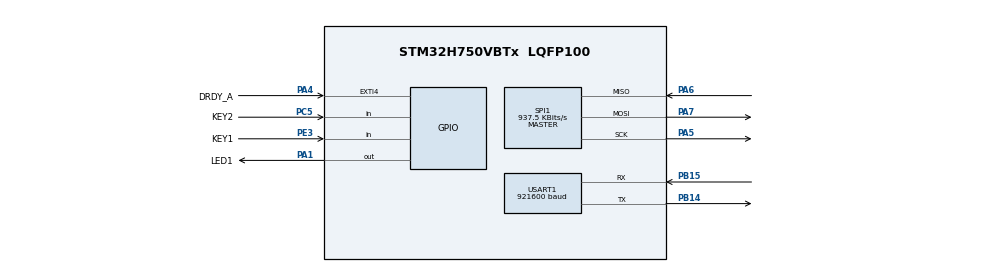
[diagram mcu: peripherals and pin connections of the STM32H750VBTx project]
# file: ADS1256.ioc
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Dma.Request0=USART1_TX
Dma.USART1_TX.0.Direction=DMA_MEMORY_TO_PERIPH
Dma.USART1_TX.0.EventEnable=DISABLE
Dma.USART1_TX.0.FIFOMode=DMA_FIFOMODE_DISABLE
Dma.USART1_TX.0.Instance=DMA1_Stream0
Dma.USART1_TX.0.MemDataAlignment=DMA_MDATAALIGN_BYTE
Dma.USART1_TX.0.MemInc=DMA_MINC_ENABLE
Dma.USART1_TX.0.Mode=DMA_NORMAL
Dma.USART1_TX.0.PeriphDataAlignment=DMA_PDATAALIGN_BYTE
Dma.USART1_TX.0.PeriphInc=DMA_PINC_DISABLE
Dma.USART1_TX.0.Polarity=HAL_DMAMUX_REQ_GEN_RISING
Dma.USART1_TX.0.Priority=DMA_PRIORITY_LOW
Dma.USART1_TX.0.RequestNumber=1
Dma.USART1_TX.0.SignalID=NONE
Dma.USART1_TX.0.SyncEnable=DISABLE
Dma.USART1_TX.0.SyncPolarity=HAL_DMAMUX_SYNC_NO_EVENT
Dma.USART1_TX.0.SyncRequestNumber=1
Dma.USART1_TX.0.SyncSignalID=NONE
FREERTOS.Tasks01=Task01,24,128,StartDefaultTask,Default,NULL,Dynamic,NULL,NULL;Task02,24,128,StartTask02,Default,NULL,Dynamic,NULL,NULL;Task03,24,128,StartTask03,Default,NULL,Dynamic,NULL,NULL
Mcu.Family=STM32H7
Mcu.Name=STM32H750VBTx
Mcu.Package=LQFP100
NVIC.DMA1_Stream0_IRQn=true\:5\:0\:false\:false\:true\:true\:false\:true
NVIC.EXTI4_IRQn=true\:5\:0\:false\:false\:true\:true\:true\:true
NVIC.PriorityGroup=NVIC_PRIORITYGROUP_4
NVIC.TIM17_IRQn=true\:0\:0\:false\:false\:true\:false\:false\:true
NVIC.TimeBase=TIM17_IRQn
NVIC.TimeBaseIP=TIM17
NVIC.USART1_IRQn=true\:5\:0\:false\:false\:true\:true\:true\:true
PA1.GPIO_Label=LED1
PA1.Signal=GPIO_Output
PA13\ (JTMS/SWDIO).Mode=Serial_Wire
PA13\ (JTMS/SWDIO).Signal=DEBUG_JTMS-SWDIO
PA14\ (JTCK/SWCLK).Mode=Serial_Wire
PA14\ (JTCK/SWCLK).Signal=DEBUG_JTCK-SWCLK
PA4.GPIO_Label=DRDY_A
PA4.GPIO_ModeDefaultEXTI=GPIO_MODE_IT_FALLING
PA4.Signal=GPXTI4
PA5.Mode=Full_Duplex_Master
PA5.Signal=SPI1_SCK
PA6.Mode=Full_Duplex_Master
PA6.Signal=SPI1_MISO
PA7.Mode=Full_Duplex_Master
PA7.Signal=SPI1_MOSI
PB14.Mode=Asynchronous
PB14.Signal=USART1_TX
PB15.Mode=Asynchronous
PB15.Signal=USART1_RX
PC5.GPIO_Label=KEY2
PC5.GPIO_PuPd=GPIO_PULLUP
PC5.Signal=GPIO_Input
PE3.GPIO_Label=KEY1
PE3.GPIO_PuPd=GPIO_PULLUP
PE3.Signal=GPIO_Input
PH0-OSC_IN\ (PH0).Mode=HSE-External-Oscillator
PH0-OSC_IN\ (PH0).Signal=RCC_OSC_IN
PH1-OSC_OUT\ (PH1).Mode=HSE-External-Oscillator
PH1-OSC_OUT\ (PH1).Signal=RCC_OSC_OUT
ProjectManager.HeapSize=0x200
ProjectManager.StackSize=0x400
ProjectManager.TargetToolchain=MDK-ARM V5.27
RCC.ADCFreq_Value=60000000
RCC.APB1Freq_Value=120000000
RCC.APB2Freq_Value=120000000
RCC.APB3Freq_Value=120000000
RCC.APB4Freq_Value=120000000
RCC.CortexFreq_Value=480000000
RCC.D1PPRE=RCC_APB3_DIV2
RCC.D2PPRE1=RCC_APB1_DIV2
RCC.D2PPRE2=RCC_APB2_DIV2
RCC.D3PPRE=RCC_APB4_DIV2
RCC.DIVM1=5
RCC.DIVM2=5
RCC.DIVM3=5
RCC.DIVN1=192
RCC.DIVN2=48
RCC.DIVN3=48
RCC.DIVP2=4
RCC.HCLKFreq_Value=240000000
RCC.HPRE=RCC_HCLK_DIV2
RCC.PLL2FRACN=0
RCC.PLLSourceVirtual=RCC_PLLSOURCE_HSE
RCC.SPI123CLockSelection=RCC_SPI123CLKSOURCE_PLL2
RCC.SYSCLKFreq_VALUE=480000000
RCC.SYSCLKSource=RCC_SYSCLKSOURCE_PLLCLK
RCC.USBFreq_Value=480000000
SPI1.BaudRatePrescaler=SPI_BAUDRATEPRESCALER_64
SPI1.CLKPhase=SPI_PHASE_2EDGE
SPI1.CalculateBaudRate=937.5 KBits/s
SPI1.DataSize=SPI_DATASIZE_8BIT
SPI1.Direction=SPI_DIRECTION_2LINES
SPI1.Mode=SPI_MODE_MASTER
SPI1.VirtualType=VM_MASTER
USART1.BaudRate=921600
USART1.OverSampling=UART_OVERSAMPLING_8
USART1.VirtualMode-Asynchronous=VM_ASYNC
VP_FREERTOS_VS_CMSIS_V2.Mode=CMSIS_V2
VP_SYS_VS_tim17.Mode=TIM17
board=custom

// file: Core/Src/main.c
/* USER CODE BEGIN Header */
/**
  ******************************************************************************
  * @file           : main.c
  * @brief          : Main program body
  ******************************************************************************
  * @attention
  *
  * <h2><center>&copy; Copyright (c) 2021 STMicroelectronics.
  * All rights reserved.</center></h2>
  *
  * This software component is licensed by ST under Ultimate Liberty license
  * SLA0044, the "License"; You may not use this file except in compliance with
  * the License. You may obtain a copy of the License at:
  *                             www.st.com/SLA0044
  *
  ******************************************************************************
  */
/* USER CODE END Header */
#include "main.h"
#include "cmsis_os.h"
#include "dma.h"
#include "spi.h"
#include "usart.h"
#include "gpio.h"

void SystemClock_Config(void);
void MX_FREERTOS_Init(void);

int main(void)
{

  /* MCU Configuration--------------------------------------------------------*/

  /* Reset of all peripherals, Initializes the Flash interface and the Systick. */
  HAL_Init();

  /* Configure the system clock */
  SystemClock_Config();

  /* Initialize all configured peripherals */
  MX_GPIO_Init();
  MX_DMA_Init();
  MX_SPI1_Init();
  MX_USART1_UART_Init();

  /* Init scheduler */
  osKernelInitialize();  /* Call init function for freertos objects (in freertos.c) */
  MX_FREERTOS_Init();
  /* Start scheduler */
  osKernelStart();

  /* We should never get here as control is now taken by the scheduler */
  /* Infinite loop */
  while (1)
  {

  }
}

void SystemClock_Config(void)
{
  RCC_OscInitTypeDef RCC_OscInitStruct = {0};
  RCC_ClkInitTypeDef RCC_ClkInitStruct = {0};

  /** Supply configuration update enable
  */
  HAL_PWREx_ConfigSupply(PWR_LDO_SUPPLY);
  /** Configure the main internal regulator output voltage
  */
  __HAL_PWR_VOLTAGESCALING_CONFIG(PWR_REGULATOR_VOLTAGE_SCALE0);

  while(!__HAL_PWR_GET_FLAG(PWR_FLAG_VOSRDY)) {}
  /** Macro to configure the PLL clock source
  */
  __HAL_RCC_PLL_PLLSOURCE_CONFIG(RCC_PLLSOURCE_HSE);
  /** Initializes the RCC Oscillators according to the specified parameters
  * in the RCC_OscInitTypeDef structure.
  */
  RCC_OscInitStruct.OscillatorType = RCC_OSCILLATORTYPE_HSE;
  RCC_OscInitStruct.HSEState = RCC_HSE_ON;
  RCC_OscInitStruct.PLL.PLLState = RCC_PLL_ON;
  RCC_OscInitStruct.PLL.PLLSource = RCC_PLLSOURCE_HSE;
  RCC_OscInitStruct.PLL.PLLM = 5;
  RCC_OscInitStruct.PLL.PLLN = 192;
  RCC_OscInitStruct.PLL.PLLP = 2;
  RCC_OscInitStruct.PLL.PLLQ = 2;
  RCC_OscInitStruct.PLL.PLLR = 2;
  RCC_OscInitStruct.PLL.PLLRGE = RCC_PLL1VCIRANGE_2;
  RCC_OscInitStruct.PLL.PLLVCOSEL = RCC_PLL1VCOWIDE;
  RCC_OscInitStruct.PLL.PLLFRACN = 0;
  if (HAL_RCC_OscConfig(&RCC_OscInitStruct) != HAL_OK)
  {
    Error_Handler();
  }
  /** Initializes the CPU, AHB and APB buses clocks
  */
  RCC_ClkInitStruct.ClockType = RCC_CLOCKTYPE_HCLK|RCC_CLOCKTYPE_SYSCLK
                              |RCC_CLOCKTYPE_PCLK1|RCC_CLOCKTYPE_PCLK2
                              |RCC_CLOCKTYPE_D3PCLK1|RCC_CLOCKTYPE_D1PCLK1;
  RCC_ClkInitStruct.SYSCLKSource = RCC_SYSCLKSOURCE_PLLCLK;
  RCC_ClkInitStruct.SYSCLKDivider = RCC_SYSCLK_DIV1;
  RCC_ClkInitStruct.AHBCLKDivider = RCC_HCLK_DIV2;
  RCC_ClkInitStruct.APB3CLKDivider = RCC_APB3_DIV2;
  RCC_ClkInitStruct.APB1CLKDivider = RCC_APB1_DIV2;
  RCC_ClkInitStruct.APB2CLKDivider = RCC_APB2_DIV2;
  RCC_ClkInitStruct.APB4CLKDivider = RCC_APB4_DIV2;

  if (HAL_RCC_ClockConfig(&RCC_ClkInitStruct, FLASH_LATENCY_4) != HAL_OK)
  {
    Error_Handler();
  }
}

 /**
  * @brief  Period elapsed callback in non blocking mode
  * @note   This function is called  when TIM17 interrupt took place, inside
  * HAL_TIM_IRQHandler(). It makes a direct call to HAL_IncTick() to increment
  * a global variable "uwTick" used as application time base.
  * @param  htim : TIM handle
  * @retval None
  */
void HAL_TIM_PeriodElapsedCallback(TIM_HandleTypeDef *htim)
{
  if (htim->Instance == TIM17) {
    HAL_IncTick();
  }
}

void Error_Handler(void)
{
  __disable_irq();
  while (1)
  {
  }
}

/************************ (C) COPYRIGHT STMicroelectronics *****END OF FILE****/

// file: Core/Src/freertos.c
/* USER CODE BEGIN Header */
/**
  ******************************************************************************
  * File Name          : freertos.c
  * Description        : Code for freertos applications
  ******************************************************************************
  * @attention
  *
  * <h2><center>&copy; Copyright (c) 2021 STMicroelectronics.
  * All rights reserved.</center></h2>
  *
  * This software component is licensed by ST under Ultimate Liberty license
  * SLA0044, the "License"; You may not use this file except in compliance with
  * the License. You may obtain a copy of the License at:
  *                             www.st.com/SLA0044
  *
  ******************************************************************************
  */
/* USER CODE END Header */

#include "FreeRTOS.h"
#include "task.h"
#include "main.h"
#include "cmsis_os.h"

/* USER CODE BEGIN Includes */
#include "Task01.h"
#include "Task02.h"
#include "Task03.h"
/* USER CODE END Includes */

/* Definitions for Task01 */
osThreadId_t Task01Handle;
const osThreadAttr_t Task01_attributes = {
  .name = "Task01",
  .stack_size = 128 * 4,
  .priority = (osPriority_t) osPriorityNormal,
};
/* Definitions for Task02 */
osThreadId_t Task02Handle;
const osThreadAttr_t Task02_attributes = {
  .name = "Task02",
  .stack_size = 128 * 4,
  .priority = (osPriority_t) osPriorityNormal,
};
/* Definitions for Task03 */
osThreadId_t Task03Handle;
const osThreadAttr_t Task03_attributes = {
  .name = "Task03",
  .stack_size = 128 * 4,
  .priority = (osPriority_t) osPriorityNormal,
};

void StartDefaultTask(void *argument);
void StartTask02(void *argument);
void StartTask03(void *argument);

void MX_FREERTOS_Init(void); /* (MISRA C 2004 rule 8.1) */

void MX_FREERTOS_Init(void) {

  /* Create the thread(s) */
  /* creation of Task01 */
  Task01Handle = osThreadNew(StartDefaultTask, NULL, &Task01_attributes);

  /* creation of Task02 */
  Task02Handle = osThreadNew(StartTask02, NULL, &Task02_attributes);

  /* creation of Task03 */
  Task03Handle = osThreadNew(StartTask03, NULL, &Task03_attributes);

}

void StartDefaultTask(void *argument)
{
  /* USER CODE BEGIN StartDefaultTask */
  /* Infinite loop */
  for(;;)
  {
		Task01Main();
    osDelay(1);
  }
  /* USER CODE END StartDefaultTask */
}

void StartTask02(void *argument)
{
  /* USER CODE BEGIN StartTask02 */
  /* Infinite loop */
  for(;;)
  {
		Task02Main();
    osDelay(1);
  }
  /* USER CODE END StartTask02 */
}

void StartTask03(void *argument)
{
  /* USER CODE BEGIN StartTask03 */
  /* Infinite loop */
  for(;;)
  {
		Task03Main();
    osDelay(1);
  }
  /* USER CODE END StartTask03 */
}

/************************ (C) COPYRIGHT STMicroelectronics *****END OF FILE****/
